AUTOSAR XML (schema 4.0)
package /ADAS_Components
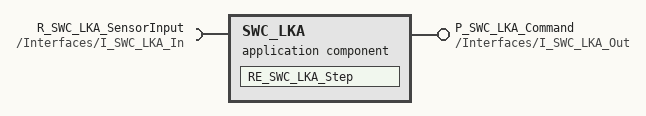
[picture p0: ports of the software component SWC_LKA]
  application sw component type SWC_LKA  # AUTOSAR Application SWC SWC_LKA for ADAS control
    provide port P_SWC_LKA_Command: provided-interface=/Interfaces/I_SWC_LKA_Out
    require port R_SWC_LKA_SensorInput: required-interface=/Interfaces/I_SWC_LKA_In
    behavior SWC_LKA_Behavior
      runnable RE_SWC_LKA_Step: symbol=SWC_LKA_Step
